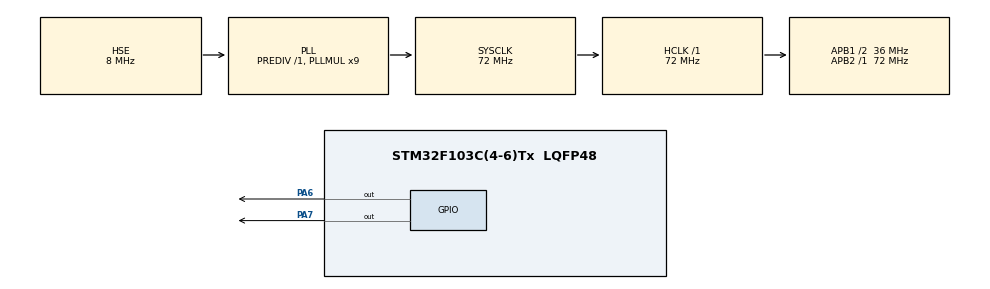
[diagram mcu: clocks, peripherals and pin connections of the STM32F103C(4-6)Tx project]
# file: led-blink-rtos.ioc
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FREERTOS.Tasks01=defaultTask,24,128,StartDefaultTask,Default,NULL,Dynamic,NULL,NULL;myTask02,24,128,StartTask02,Default,NULL,Dynamic,NULL,NULL
FREERTOS.configUSE_NEWLIB_REENTRANT=1
Mcu.Family=STM32F1
Mcu.Name=STM32F103C(4-6)Tx
Mcu.Package=LQFP48
NVIC.PriorityGroup=NVIC_PRIORITYGROUP_4
NVIC.TIM1_UP_IRQn=true\:15\:0\:false\:false\:true\:false\:false\:true\:true
NVIC.TimeBase=TIM1_UP_IRQn
NVIC.TimeBaseIP=TIM1
PA6.Signal=GPIO_Output
PA7.Signal=GPIO_Output
PD0-OSC_IN.Mode=HSE-External-Oscillator
PD0-OSC_IN.Signal=RCC_OSC_IN
PD1-OSC_OUT.Mode=HSE-External-Oscillator
PD1-OSC_OUT.Signal=RCC_OSC_OUT
ProjectManager.HeapSize=0x200
ProjectManager.StackSize=0x400
ProjectManager.TargetToolchain=STM32CubeIDE
RCC.AHBFreq_Value=72000000
RCC.APB1CLKDivider=RCC_HCLK_DIV2
RCC.APB1Freq_Value=36000000
RCC.APB1TimFreq_Value=72000000
RCC.APB2Freq_Value=72000000
RCC.APB2TimFreq_Value=72000000
RCC.HCLKFreq_Value=72000000
RCC.PLLMUL=RCC_PLL_MUL9
RCC.PLLSourceVirtual=RCC_PLLSOURCE_HSE
RCC.SYSCLKFreq_VALUE=72000000
RCC.SYSCLKSource=RCC_SYSCLKSOURCE_PLLCLK
RCC.USBFreq_Value=72000000
VP_FREERTOS_VS_CMSIS_V2.Mode=CMSIS_V2
VP_SYS_VS_ND.Mode=No_Debug
VP_SYS_VS_tim1.Mode=TIM1
board=custom

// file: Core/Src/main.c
/* USER CODE BEGIN Header */
/**
  ******************************************************************************
  * @file           : main.c
  * @brief          : Main program body (FreeRTOS API)
  ******************************************************************************
  * @attention
  *
  * Copyright (c) 2025 STMicroelectronics.
  * All rights reserved.
  *
  * This software is licensed under terms that can be found in the LICENSE file
  * in the root directory of this software component.
  * If no LICENSE file comes with this software, it is provided AS-IS.
  *
  ******************************************************************************
  */
/* USER CODE END Header */

#include "main.h"
/* Remove CMSIS-RTOS header */
/* #include "cmsis_os.h" */

/* USER CODE BEGIN Includes */
#include "FreeRTOS.h"
#include "task.h"
/* USER CODE END Includes */

/* USER CODE BEGIN PV */
TaskHandle_t defaultTaskHandle;
TaskHandle_t myTask02Handle;
/* USER CODE END PV */

void SystemClock_Config(void);
static void MX_GPIO_Init(void);
void StartDefaultTask(void *argument);
void StartTask02(void *argument);

int main(void)
{

  /* MCU Configuration--------------------------------------------------------*/
  HAL_Init();
  SystemClock_Config();
  MX_GPIO_Init();

  /* USER CODE BEGIN 2 */
  /* Create FreeRTOS tasks instead of osThreads */
  xTaskCreate(
    StartDefaultTask,         /* Task function       */
    "defaultTask",            /* Name for debugging  */
    128,                      /* Stack depth in words*/
    NULL,                     /* Task parameters     */
    tskIDLE_PRIORITY + 1,     /* Task priority       */
    &defaultTaskHandle        /* Task handle         */
  );

  xTaskCreate(
    StartTask02,
    "myTask02",
    128,
    NULL,
    tskIDLE_PRIORITY + 1,
    &myTask02Handle
  );

  /* Start the scheduler */
  vTaskStartScheduler();
  /* USER CODE END 2 */

  /* We should never get here as control is now taken by the scheduler */
  while (1)
  {
    /* Fallback in case of scheduler failure */
  }
}

void SystemClock_Config(void)
{
  RCC_OscInitTypeDef RCC_OscInitStruct = {0};
  RCC_ClkInitTypeDef RCC_ClkInitStruct = {0};

  RCC_OscInitStruct.OscillatorType = RCC_OSCILLATORTYPE_HSE;
  RCC_OscInitStruct.HSEState       = RCC_HSE_ON;
  RCC_OscInitStruct.HSEPredivValue = RCC_HSE_PREDIV_DIV1;
  RCC_OscInitStruct.HSIState       = RCC_HSI_ON;
  RCC_OscInitStruct.PLL.PLLState   = RCC_PLL_ON;
  RCC_OscInitStruct.PLL.PLLSource  = RCC_PLLSOURCE_HSE;
  RCC_OscInitStruct.PLL.PLLMUL     = RCC_PLL_MUL9;
  if (HAL_RCC_OscConfig(&RCC_OscInitStruct) != HAL_OK)
    Error_Handler();

  RCC_ClkInitStruct.ClockType      = RCC_CLOCKTYPE_HCLK
                                   | RCC_CLOCKTYPE_SYSCLK
                                   | RCC_CLOCKTYPE_PCLK1
                                   | RCC_CLOCKTYPE_PCLK2;
  RCC_ClkInitStruct.SYSCLKSource   = RCC_SYSCLKSOURCE_PLLCLK;
  RCC_ClkInitStruct.AHBCLKDivider  = RCC_SYSCLK_DIV1;
  RCC_ClkInitStruct.APB1CLKDivider = RCC_HCLK_DIV2;
  RCC_ClkInitStruct.APB2CLKDivider = RCC_HCLK_DIV1;
  if (HAL_RCC_ClockConfig(&RCC_ClkInitStruct, FLASH_LATENCY_2) != HAL_OK)
    Error_Handler();
}

static void MX_GPIO_Init(void)
{
  GPIO_InitTypeDef GPIO_InitStruct = {0};

  __HAL_RCC_GPIOD_CLK_ENABLE();
  __HAL_RCC_GPIOA_CLK_ENABLE();

  HAL_GPIO_WritePin(GPIOA, GPIO_PIN_6|GPIO_PIN_7, GPIO_PIN_RESET);

  GPIO_InitStruct.Pin   = GPIO_PIN_6|GPIO_PIN_7;
  GPIO_InitStruct.Mode  = GPIO_MODE_OUTPUT_PP;
  GPIO_InitStruct.Pull  = GPIO_NOPULL;
  GPIO_InitStruct.Speed = GPIO_SPEED_FREQ_LOW;
  HAL_GPIO_Init(GPIOA, &GPIO_InitStruct);
}

void StartDefaultTask(void *argument)
{
  /* Infinite loop */
  for(;;)
  {
	HAL_GPIO_TogglePin(GPIOA, GPIO_PIN_6);
    vTaskDelay(pdMS_TO_TICKS(1));
  }
}

void StartTask02(void *argument)
{
  /* Infinite loop */
  for(;;)
  {
    HAL_GPIO_TogglePin(GPIOA, GPIO_PIN_7);
    vTaskDelay(pdMS_TO_TICKS(1000));
  }
}

void HAL_TIM_PeriodElapsedCallback(TIM_HandleTypeDef *htim)
{
  if (htim->Instance == TIM1)
  {
    HAL_IncTick();
  }
}

void Error_Handler(void)
{
  __disable_irq();
  while (1)
  {
  }
}
